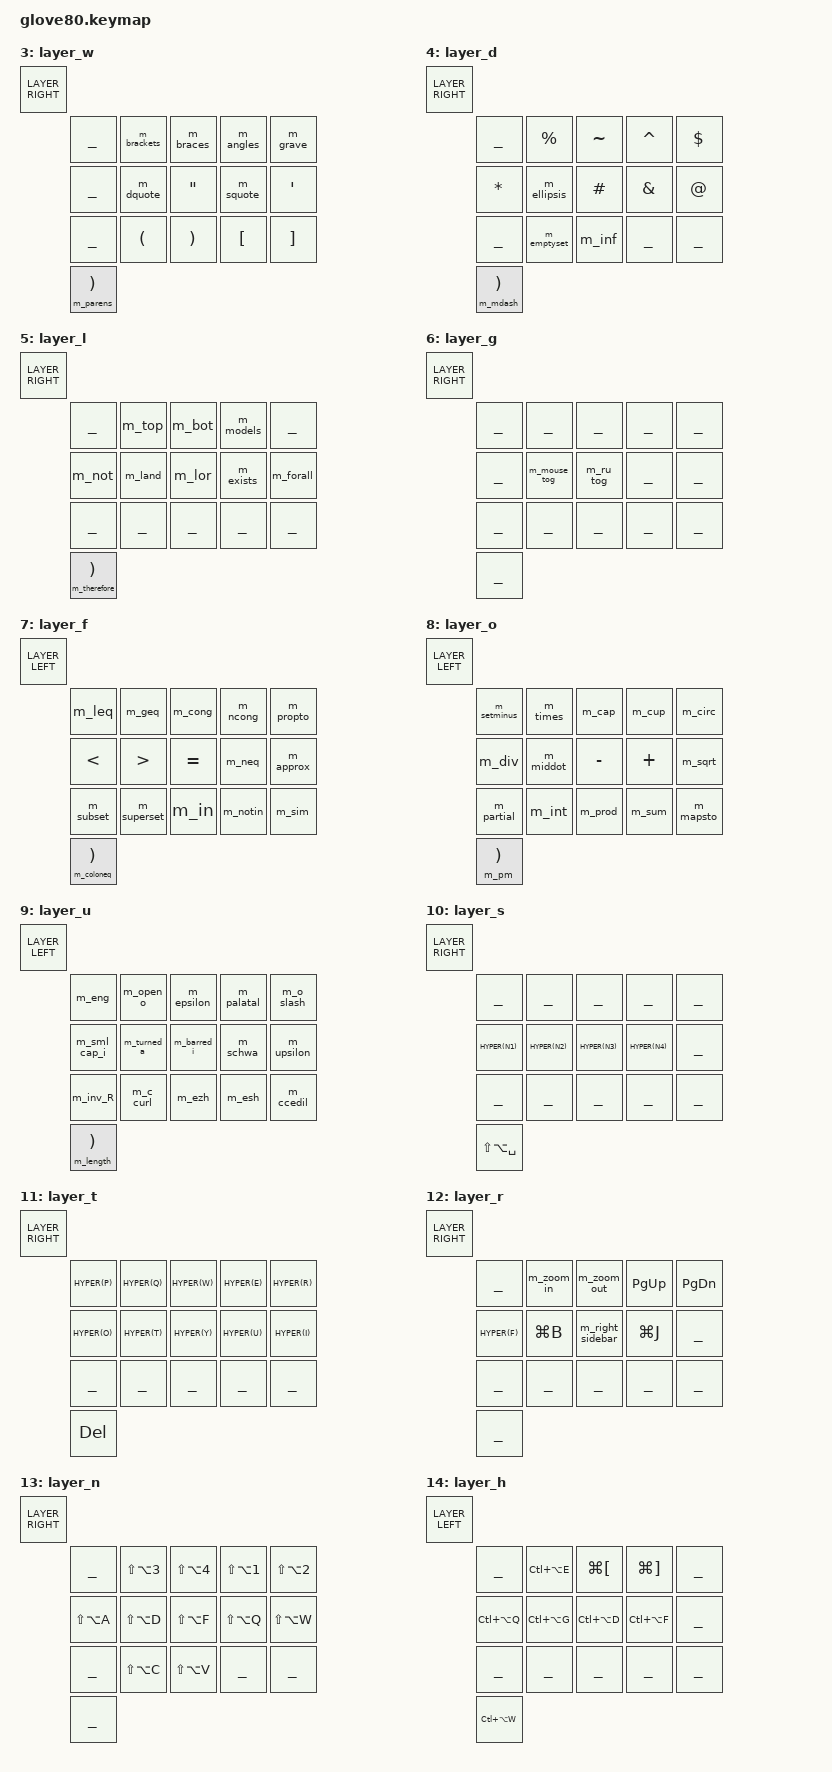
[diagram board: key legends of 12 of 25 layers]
/*
 * Glove80 keymap — QWERTY alphas (HID letter codes).
 *
 * macOS input source: U.S. QWERTY. Layer holds stay on the same finger positions
 * as the old Graphite layout (e.g. Primary apps = left-index F).
 * Mac builtin layers are Goku/Karabiner (:is_built_in_keyboard only).
 *
 * Shared actions (apps, window mgmt) emit chords; Hammerspoon runs the scripts.
 * Karabiner must not handle Glove80.
 *
 * Unicode macros: F15 + 4 hex digits → Hammerspoon keyStrokes (see unicode_leader.lua).
 * No macOS Unicode Hex Input required.
 */

#include <behaviors.dtsi>
#include <dt-bindings/zmk/keys.h>
#include <dt-bindings/zmk/modifiers.h>
#include <dt-bindings/zmk/bt.h>
#include <dt-bindings/zmk/ext_power.h>
#include <dt-bindings/zmk/outputs.h>
#include <dt-bindings/zmk/rgb.h>
#include <dt-bindings/zmk/pointing.h>

#include "layout_helpers.dtsi"

// Layer indices — must match declaration order in `keymap` below.
// L_RU must sit *below* letter/thumb layers so hold-layers still win while Russian is on.
#define DEFAULT 0
#define L_RU    1   // Vestnik Russian (tap RCTRL) — under letter layers
#define LOWER   2
#define L_W     3   // QWERTY R — Dual punctuation (was Graphite W)
#define L_D     4   // QWERTY E — Solo punctuation (was Graphite D)
#define L_L     5   // QWERTY W — Logic symbols (was Graphite L)
#define L_G     6   // hold G — J toggles mouse, K toggles Russian
#define L_F     7   // QWERTY U — Math relations (was Graphite F)
#define L_O     8   // QWERTY I — Math operators (was Graphite O)
#define L_U     9   // QWERTY O — IPA (was Graphite U)
#define L_S     10  // QWERTY F — Primary apps (was Graphite S)
#define L_T     11  // QWERTY D — Secondary apps (was Graphite T)
#define L_R     12  // QWERTY S — Inner app nav (was Graphite R)
#define L_N     13  // QWERTY A — Window management (was Graphite N)
#define L_H     14  // QWERTY J — Browser (was Graphite H)
#define L_A     15  // QWERTY K — Clipboard (was Graphite A)
#define L_E     16  // QWERTY L — Text selection (was Graphite E)
#define L_I     17  // QWERTY ; — Find & navigate (was Graphite I)
#define L_AUDIO 18  // LT5 hold — Audio & display
#define L_WNAV  19  // QWERTY , hold — Word navigation (was Graphite .)
#define L_WDEL  20  // QWERTY M hold — Word deletion (was Graphite P)
#define L_GAME  21  // tap RT3 — plain keys (no letter/thumb layers)
#define L_MOUSE 22  // hold G, tap J — mouse (bottom-row move)
#define MAGIC   23
#define FACTORY_TEST 24

// Built-in layer-tap (&lt): hold → momentary layer, tap → key.
&lt {
    flavor = "tap-preferred";
    tapping-term-ms = <280>;
    quick-tap-ms = <280>;
};

/ {
    behaviors {
        // Stock Lower: hold = momentary, double-tap = toggle
        layer_td: tap_dance_0 {
            compatible = "zmk,behavior-tap-dance";
            label = "LAYER_TAP_DANCE";
            #binding-cells = <0>;
            tapping-term-ms = <200>;
            bindings = <&mo LOWER>, <&to LOWER>;
        };

        magic: magic_hold_tap {
            compatible = "zmk,behavior-hold-tap";
            label = "MAGIC_HOLD_TAP";
            #binding-cells = <2>;
            flavor = "tap-preferred";
            tapping-term-ms = <200>;
            bindings = <&mo>, <&rgb_ug_status_macro>;
        };

        // QWERTY comma: tap , / shift < ; hold → Word-Nav
        mm_comma: mod_morph_comma {
            compatible = "zmk,behavior-mod-morph";
            #binding-cells = <0>;
            bindings = <&kp COMMA>, <&kp LT>;
            mods = <(MOD_LSFT|MOD_RSFT)>;
        };
        comma_wnav: hold_tap_comma_wnav {
            compatible = "zmk,behavior-hold-tap";
            #binding-cells = <2>;
            flavor = "tap-preferred";
            tapping-term-ms = <280>;
            bindings = <&mo>, <&mm_comma>;
        };
        // Bracket keys: [/{ and ]/} (stock QWERTY)
        mm_lbkt: mod_morph_lbkt {
            compatible = "zmk,behavior-mod-morph";
            #binding-cells = <0>;
            bindings = <&kp LBKT>, <&kp LBRC>;
            mods = <(MOD_LSFT|MOD_RSFT)>;
        };
        mm_rbkt: mod_morph_rbkt {
            compatible = "zmk,behavior-mod-morph";
            #binding-cells = <0>;
            bindings = <&kp RBKT>, <&kp RBRC>;
            mods = <(MOD_LSFT|MOD_RSFT)>;
        };
    };

    macros {
        rgb_ug_status_macro: rgb_ug_status_macro_0 {
            label = "RGB_UG_STATUS";
            compatible = "zmk,behavior-macro";
            #binding-cells = <0>;
            bindings = <&rgb_ug RGB_STATUS>;
        };

        bt_0: bt_profile_macro_0 {
            label = "BT_0";
            compatible = "zmk,behavior-macro";
            #binding-cells = <0>;
            bindings = <&out OUT_BLE>, <&bt BT_SEL 0>;
        };
        bt_1: bt_profile_macro_1 {
            label = "BT_1";
            compatible = "zmk,behavior-macro";
            #binding-cells = <0>;
            bindings = <&out OUT_BLE>, <&bt BT_SEL 1>;
        };
        bt_2: bt_profile_macro_2 {
            label = "BT_2";
            compatible = "zmk,behavior-macro";
            #binding-cells = <0>;
            bindings = <&out OUT_BLE>, <&bt BT_SEL 2>;
        };
        bt_3: bt_profile_macro_3 {
            label = "BT_3";
            compatible = "zmk,behavior-macro";
            #binding-cells = <0>;
            bindings = <&out OUT_BLE>, <&bt BT_SEL 3>;
        };

        // Shift+/ morph target: bare BSLH while Shift is still held → pipe on macOS.
        m_bslash: m_bslash {
            compatible = "zmk,behavior-macro";
            #binding-cells = <0>;
            wait-ms = <0>;
            tap-ms = <5>;
            bindings
                = <&macro_release &kp LSHFT>
                , <&macro_release &kp RSHFT>
                , <&macro_tap &kp BSLH>;
        };

        // Explicit mod order for app zoom (F3/F4 + R-layer F/O)
        m_zoom_in: m_zoom_in {
            compatible = "zmk,behavior-macro";
            #binding-cells = <0>;
            wait-ms = <0>;
            tap-ms = <5>;
            bindings
                = <&macro_press &kp LGUI>
                , <&macro_tap &kp EQUAL>
                , <&macro_release &kp LGUI>;
        };
        m_zoom_out: m_zoom_out {
            compatible = "zmk,behavior-macro";
            #binding-cells = <0>;
            wait-ms = <0>;
            tap-ms = <5>;
            bindings
                = <&macro_press &kp LGUI>
                , <&macro_tap &kp MINUS>
                , <&macro_release &kp LGUI>;
        };

        // Cmd+Opt+B — reliable mod order for Cursor auxiliary / chat sidebar
        m_right_sidebar: m_right_sidebar {
            compatible = "zmk,behavior-macro";
            #binding-cells = <0>;
            wait-ms = <0>;
            tap-ms = <5>;
            bindings
                = <&macro_press &kp LGUI>
                , <&macro_press &kp LALT>
                , <&macro_tap &kp B>
                , <&macro_release &kp LALT>
                , <&macro_release &kp LGUI>;
        };

        // Dual punctuation wrappers (type pair, cursor between)
        WRAP(m_parens,   LPAR,  RPAR);
        WRAP(m_brackets, LBKT,  RBKT);
        WRAP(m_braces,   LBRC,  RBRC);
        WRAP(m_dquote,   DQT,   DQT);
        WRAP(m_squote,   SQT,   SQT);
        WRAP(m_grave,    GRAVE, GRAVE);
        UC2_LEFT(m_angles, N2, N7, E, N8, N2, N7, E, N9); // ⟨⟩ then Left

        // macOS Unicode Hex Input (Option + 4 hex digits)
        UC(m_equiv,     N2, N2, N6, N1); // ≡
        UC(m_nequiv,    N2, N2, N6, N2); // ≢
        UC(m_sim,       N2, N2, N3, C);  // ∼
        UC(m_approx,    N2, N2, N4, N8); // ≈
        UC(m_coloneq,   N2, N2, N5, N4); // ≔
        UC(m_in,        N2, N2, N0, N8); // ∈
        UC(m_notin,     N2, N2, N0, N9); // ∉
        UC(m_subseteq,  N2, N2, N8, N6); // ⊆
        UC(m_supseteq,  N2, N2, N8, N7); // ⊇
        UC(m_subset,    N2, N2, N8, N2); // ⊂
        UC(m_superset,  N2, N2, N8, N3); // ⊃
        UC(m_nsubset,   N2, N2, N8, N4); // ⊄
        UC(m_nsuperset, N2, N2, N8, N5); // ⊅
        UC(m_cong,      N2, N2, N4, N5); // ≅
        UC(m_ncong,     N2, N2, N4, N7); // ≇
        UC(m_propto,    N2, N2, N1, D);  // ∝
        UC(m_ni,        N2, N2, N0, B);  // ∋
        UC(m_notni,     N2, N2, N0, C);  // ∌
        UC(m_circ,      N2, N2, N1, N8); // ∘
        UC(m_mapsto,    N2, N1, A,  N6); // ↦
        UC(m_times,     N0, N0, D,  N7); // ×
        UC(m_div,       N0, N0, F,  N7); // ÷
        UC(m_sqrt,      N2, N2, N1, A);  // √
        UC(m_cap,       N2, N2, N2, N9); // ∩
        UC(m_cup,       N2, N2, N2, A);  // ∪
        UC(m_setminus,  N2, N2, N1, N6); // ∖
        UC(m_sum,       N2, N2, N1, N1); // ∑
        UC(m_prod,      N2, N2, N0, F);  // ∏
        UC(m_int,       N2, N2, N2, B);  // ∫
        UC(m_partial,   N2, N2, N0, N2); // ∂
        UC(m_lrarr,     N2, N1, N9, N4); // ↔
        UC(m_oplus,     N2, N2, N9, N5); // ⊕
        UC(m_otimes,    N2, N2, N9, N7); // ⊗
        UC(m_odot,      N2, N2, N9, N9); // ⊙
        UC(m_rarr,      N2, N1, N9, N2); // →
        UC(m_larr,      N2, N1, N9, N0); // ←
        UC(m_uarr,      N2, N1, N9, N1); // ↑
        UC(m_darr,      N2, N1, N9, N3); // ↓
        UC(m_land,      N2, N2, N2, N7); // ∧
        UC(m_lor,       N2, N2, N2, N8); // ∨
        UC(m_exists,    N2, N2, N0, N3); // ∃
        UC(m_forall,    N2, N2, N0, N0); // ∀
        UC(m_implies,   N2, N7, F,  N9); // ⟹
        UC(m_iff,       N2, N7, F,  A);  // ⟺
        UC(m_vdash,     N2, N2, A,  N2); // ⊢
        UC(m_models,    N2, N2, A,  N8); // ⊨
        UC(m_top,       N2, N2, A,  N4); // ⊤
        UC(m_bot,       N2, N2, A,  N5); // ⊥
        UC(m_therefore, N2, N2, N3, N4); // ∴
        UC(m_inf,       N2, N2, N1, E);  // ∞
        UC(m_emptyset,  N2, N2, N0, N5); // ∅
        UC(m_ellipsis,  N2, N0, N2, N6); // …
        UC(m_mdash,     N2, N0, N1, N4); // —
        UC(m_leq,       N2, N2, N6, N4); // ≤
        UC(m_geq,       N2, N2, N6, N5); // ≥
        UC(m_neq,       N2, N2, N6, N0); // ≠
        UC(m_middot,    N0, N0, B,  N7); // ·
        UC(m_pm,        N0, N0, B,  N1); // ±

        // IPA (Graphite U) — RU > DE > EN, non-Latin, by frequency
        UC(m_palatal,   N0, N2, B,  N2); // ʲ
        UC(m_schwa,     N0, N2, N5, N9); // ə
        UC(m_barred_i,  N0, N2, N6, N8); // ɨ
        UC(m_esh,       N0, N2, N8, N3); // ʃ
        UC(m_ezh,       N0, N2, N9, N2); // ʒ
        UC(m_c_curl,    N0, N2, N5, N5); // ɕ
        UC(m_turned_a,  N0, N2, N5, N0); // ɐ
        UC(m_ccedil,    N0, N0, E,  N7); // ç
        UC(m_inv_R,     N0, N2, N8, N1); // ʁ
        UC(m_eng,       N0, N1, N4, B);  // ŋ
        UC(m_sml_cap_i, N0, N2, N6, A);  // ɪ
        UC(m_upsilon,   N0, N2, N8, A);  // ʊ
        UC(m_open_o,    N0, N2, N5, N4); // ɔ
        UC(m_epsilon,   N0, N2, N5, B);  // ɛ
        UC(m_o_slash,   N0, N0, F,  N8); // ø
        UC(m_length,    N0, N2, D,  N0); // ː

        UC(m_not,       N0, N0, A,  C);  // ¬

#include "russian_macros.inc"
    };

    behaviors {
#include "russian_behaviors.inc"
    };

    keymap {
        compatible = "zmk,keymap";

        // =====================================================================
        // DEFAULT — QWERTY letter HID
        //   q w e r t  y u i o p
        //   a s d f g  h j k l ;
        //   z x c v b  n m , . /
        // =====================================================================
        default_layer {
            // ---------------------------------------------------------------------------------------------------------------------------------
            // | BRIDN | BRIUP | ZOOM+ | ZOOM- | none |                                                               | NEXT  |  PP   | MUTE | VOLDN | VOLUP |
            // | none  |  1  |  2  |  3   |  4   |  5   |                                                 |  6   |   7   |   8   |  9   |   0   |  =/+ |
            // |  ESC  |  B  |  L  |  D   |  W   |  Z   |                                                 |  ,   |   F   |   O   |  U   |   J   |   \  |
            // | none  |  N  |  R  |  T   |  S   |  G   |                                                 |  Y   |   H   |   A   |  E   |   I   |   '  |
            // | none  |  Q  |  X  |  M   |  C   |  V   | LSHFT | LCTRL | LGUI  | | RGUI  | RU/RC | RSHFT |  K   |   P   |   .   |  -   |   /   | none |
            // | MAGIC | none | none | LEFT | RIGHT|      | BSPC  | TAB   | CAPS  | | RALT  | RET   | SPACE |      |  UP   | DOWN  |  [   |   ]   | none |
            // Thumbs (see keybindings.txt THUMB KEY IDS):
            // LT1/RT1 tap Caps, hold Shift; LT2 Ctrl; LT3 Cmd
            // LT4 Bspc; LT5 Audio hold (tap none); LT6 Tab
            // RT2 Ctrl(+RU tap); RT3 Cmd(+game tap); RT4–6 Space|Enter|Alt
            // Word-Nav = hold Graphite . ; Word-Del = hold Graphite P
            // Under Esc = left click; right of ; / ] = PgUp / PgDn

            bindings = <
            &kp C_BRI_DN   &kp C_BRI_UP &m_zoom_in   &m_zoom_out  &none                                                                                         &kp C_NEXT &kp C_PP    &kp C_MUTE  &kp C_VOL_DN &kp C_VOL_UP
            &none          &kp N1   &kp N2      &kp N3      &kp N4      &kp N5                                                                     &kp N6  &kp N7  &kp N8      &kp N9      &kp N0      &kp EQUAL
            &kp ESC        &kp Q     &lt L_L W   &lt L_D E   &lt L_W R   &kp T                                                                      &kp Y   &lt L_F U  &lt L_O I  &lt L_U O  &kp P       &kp BSLH
            &mkp LCLK      &lt L_N A &lt L_R S  &lt L_T D   &lt L_S F   &lt L_G G                                                                  &kp H   &lt L_H J  &lt L_A K  &lt L_E L  &lt L_I SEMI   &kp SQT
            &none          &kp Z    &kp X       &kp C       &kp V       &kp B   &shift_caps LSHFT CAPS   &kp LCTRL   &kp LGUI  &game_cmd RGUI 0  &ru_on RCTRL 0 &shift_caps RSHFT CAPS   &kp N   &lt L_WDEL M   &comma_wnav L_WNAV 0   &kp DOT   &kp FSLH    &kp PG_UP
            &magic MAGIC 0 &none &none &kp LEFT &kp RIGHT        &kp BSPC    &mo L_AUDIO &kp TAB &kp RALT &kp RET &kp SPACE &kp UP &kp DOWN &mm_lbkt &mm_rbkt &kp PG_DN
            >;
        };

        // =====================================================================
        // RUSSIAN — Vestnik (same QWERTY letters; HS remaps to Cyrillic)
        // Same edges/thumbs as default except LT5 tap = stress.
        // =====================================================================
        russian_layer {
            bindings = <
            &kp C_BRI_DN   &kp C_BRI_UP &m_zoom_in   &m_zoom_out  &none                                                                                         &kp C_NEXT &kp C_PP    &kp C_MUTE  &kp C_VOL_DN &kp C_VOL_UP
            &none          &kp N1   &kp N2      &kp N3      &kp N4      &kp N5                                                                     &kp N6  &kp N7  &kp N8      &kp N9      &kp N0      &kp EQUAL
            &kp ESC        &kp Q        &lt L_L W   &lt L_D E   &lt L_W R   &kp T                                                                        &kp Y &lt L_F U &lt L_O I &lt L_U O &kp P &kp BSLH
            &mkp LCLK      &lt L_N A    &lt L_R S   &lt L_T D   &lt L_S F   &lt L_G G                                                                    &kp H &lt L_H J &lt L_A K &lt L_E L &lt L_I SEMI &kp SQT
            &none          &kp Z        &kp X       &kp C       &kp V       &kp B   &shift_caps LSHFT CAPS &kp LCTRL &kp LGUI  &game_cmd RGUI 0  &ru_off RCTRL 0 &shift_caps RSHFT CAPS   &kp N &lt L_WDEL M &lt L_WNAV COMMA &kp DOT &kp FSLH &kp PG_UP
            &magic MAGIC 0 &none        &none       &kp LEFT    &kp RIGHT                    &kp BSPC &ru_tab L_AUDIO 0 &kp TAB &kp RALT &kp RET &kp SPACE &kp UP &kp DOWN &kp LBKT &kp RBKT &kp PG_DN
            >;
        };

        // Stock Lower layer (unchanged from MoErgo default)
        lower_layer {
            bindings = <
            &kp C_BRI_DN      &kp C_BRI_UP        &kp C_PREV      &kp C_NEXT      &kp C_PP                                                                                                           &kp C_MUTE   &kp C_VOL_DN &kp C_VOL_UP  &none           &kp PAUSE_BREAK
            &trans            &none               &none           &none           &none           &kp HOME                                                                              &kp LPAR     &kp KP_NUM   &kp KP_EQUAL &kp KP_DIVIDE &kp KP_MULTIPLY &kp PSCRN
            &trans            &none               &none           &kp UP          &none           &kp END                                                                               &kp RPAR     &kp KP_N7    &kp KP_N8    &kp KP_N9     &kp KP_MINUS    &kp SLCK
            &trans            &none               &kp LEFT        &kp DOWN        &kp RIGHT       &kp PG_UP                                                                             &kp PRCNT    &kp KP_N4    &kp KP_N5    &kp KP_N6     &kp KP_PLUS     &none
            &trans            &kp K_CMENU         &none           &kp F11         &kp F12         &kp PG_DN       &trans      &trans      &to DEFAULT &trans      &trans      &trans    &kp COMMA    &kp KP_N1    &kp KP_N2    &kp KP_N3     &kp KP_ENTER    &trans
            &trans            &kp CAPS            &kp INS         &kp F11         &kp F12                         &trans      &trans      &trans      &trans      &trans      &trans                 &kp KP_N0    &kp KP_N0    &kp KP_DOT    &kp KP_ENTER    &trans
            >;
        };

        // =====================================================================
        // Layers — opposite-hand only via LAYER_LEFT / LAYER_RIGHT
        // Args are QWERTY positions; comments note Graphite roles.
        // LAYER_RIGHT(y,u,i,o,p,  h,j,k,l,;,  n,m,,,.,/,  space)
        // LAYER_LEFT (q,w,e,r,t,  a,s,d,f,g,  z,x,c,v,b,  space)
        // =====================================================================

        // =====================================================================
        // UPPER LEFT (inward → outward): W D L
        // =====================================================================

        // Graphite W, QWERTY R — Dual punctuation
        // Upper: wrap pairs; home: quotes; bottom: single open/close; Space = ()
        layer_w {
            bindings = <
            LAYER_RIGHT(
                ___, &m_brackets, &m_braces, &m_angles, &m_grave,
                ___, &m_dquote, &kp DQT, &m_squote, &kp SQT,
                ___, &kp LPAR, &kp RPAR, &kp LBKT, &kp RBKT,
                &m_parens
            )
            >;
        };

        // Graphite D, QWERTY E — Solo punctuation
        layer_d {
            bindings = <
            LAYER_RIGHT(
                ___, &kp PRCNT, &kp TILDE, &kp CARET, &kp DLLR,
                &kp STAR, &m_ellipsis, &kp HASH, &kp AMPS, &kp AT,
                ___, &m_emptyset, &m_inf, ___, ___,
                &m_mdash
            )
            >;
        };

        // Graphite L, QWERTY W — Logic symbols (was B)
        // F⊤ O⊥ U⊨ | Y¬ H∧ A∨ E∃ I∀ | Space∴
        layer_l {
            bindings = <
            LAYER_RIGHT(
                ___, &m_top, &m_bot, &m_models, ___,
                &m_not, &m_land, &m_lor, &m_exists, &m_forall,
                ___, ___, ___, ___, ___,
                &m_therefore
            )
            >;
        };

        // Hold G: H = toggle mouse, A = toggle Russian
        layer_g {
            bindings = <
            LAYER_RIGHT(
                ___, ___, ___, ___, ___,
                ___, &m_mouse_tog, &m_ru_tog, ___, ___,
                ___, ___, ___, ___, ___,
                ___
            )
            >;
        };

        // =====================================================================
        // UPPER RIGHT (inward → outward): F O U
        // =====================================================================

        // Graphite F, QWERTY U — Math relations (rows cycled LEFT)
        // B≤ L≥ D≅ W≇ Z∝ | N< R> T= S≠ G≈ | Q⊂ X⊃ M∈ C∉ V∼ | Space≔
        layer_f {
            bindings = <
            LAYER_LEFT(
                &m_leq, &m_geq, &m_cong, &m_ncong, &m_propto,
                &kp LT, &kp GT, &kp EQUAL, &m_neq, &m_approx,
                &m_subset, &m_superset, &m_in, &m_notin, &m_sim,
                &m_coloneq
            )
            >;
        };

        // Graphite O, QWERTY I — Math operators
        // B∖ L× D∩ W∪ Z∘ | N÷ R· T- S+ G√ | Q∂ X∫ M∏ C∑ V↦ | Space±
        layer_o {
            bindings = <
            LAYER_LEFT(
                &m_setminus, &m_times, &m_cap, &m_cup, &m_circ,
                &m_div, &m_middot, &kp MINUS, &kp PLUS, &m_sqrt,
                &m_partial, &m_int, &m_prod, &m_sum, &m_mapsto,
                &m_pm
            )
            >;
        };

        // Graphite U, QWERTY O — IPA (upper↔middle flipped)
        // Bŋ Lɔ Dɛ Wʲ Zø | Nɪ Rɐ Tɨ Sə Gʊ | Qʁ Xɕ Mʒ Cʃ Vç | Spaceː
        layer_u {
            bindings = <
            LAYER_LEFT(
                &m_eng, &m_open_o, &m_epsilon, &m_palatal, &m_o_slash,
                &m_sml_cap_i, &m_turned_a, &m_barred_i, &m_schwa, &m_upsilon,
                &m_inv_R, &m_c_curl, &m_ezh, &m_esh, &m_ccedil,
                &m_length
            )
            >;
        };

        // =====================================================================
        // HOME LEFT (inward → outward): S T R N
        // =====================================================================

        // Graphite S, QWERTY F — Primary apps (was H; flipped to right hand)
        // Y/H/A/E = apps 1-4
        layer_s {
            bindings = <
            LAYER_RIGHT(
                ___, ___, ___, ___, ___,
                &kp HYPER(N1), &kp HYPER(N2), &kp HYPER(N3), &kp HYPER(N4), ___,
                ___, ___, ___, ___, ___,
                &kp LS(LA(SPACE))
            )
            >;
        };

        // Graphite T, QWERTY D — Secondary apps (was S)
        // Upper: F WhatsApp … J Calendar; Y Messages; , Spotify; Space = Delete
        layer_t {
            bindings = <
            LAYER_RIGHT(
                &kp HYPER(P), &kp HYPER(Q), &kp HYPER(W), &kp HYPER(E), &kp HYPER(R),
                &kp HYPER(O), &kp HYPER(T), &kp HYPER(Y), &kp HYPER(U), &kp HYPER(I),
                ___, ___, ___, ___, ___,
                &kp DEL
            )
            >;
        };

        // Graphite R, QWERTY S — Inner app nav (was A; flipped to right)
        // Y focus editor; H/A/E sidebars (Cursor: open/focus, close if focused)
        layer_r {
            bindings = <
            LAYER_RIGHT(
                ___, &m_zoom_in, &m_zoom_out, &kp PG_UP, &kp PG_DN,
                &kp HYPER(F), &kp LG(B), &m_right_sidebar, &kp LG(J), ___,
                ___, ___, ___, ___, ___,
                ___
            )
            >;
        };

        // Graphite N, QWERTY A — Window management
        // F/O send ws; U/J go ws; P/. resize; Y swap; H/A focus; E accordion; I split
        layer_n {
            bindings = <
            LAYER_RIGHT(
                ___, &kp LS(LA(N3)), &kp LS(LA(N4)), &kp LS(LA(N1)), &kp LS(LA(N2)),
                &kp LS(LA(A)), &kp LS(LA(D)), &kp LS(LA(F)), &kp LS(LA(Q)), &kp LS(LA(W)),
                ___, &kp LS(LA(C)), &kp LS(LA(V)), ___, ___,
                ___
            )
            >;
        };

        // =====================================================================
        // HOME RIGHT (inward → outward): H A E I
        // =====================================================================

        // Graphite H, QWERTY J — Browser (was T; flipped to left)
        // D/W links; L split; R new; T prev; S next; N switch spaces
        layer_h {
            bindings = <
            LAYER_LEFT(
                ___, &kp LC(LA(E)), &kp LG(LBKT), &kp LG(RBKT), ___,
                &kp LC(LA(Q)), &kp LC(LA(G)), &kp LC(LA(D)), &kp LC(LA(F)), ___,
                ___, ___, ___, ___, ___,
                &kp LC(LA(W))
            )
            >;
        };

        // Graphite A, QWERTY K — Clipboard & edit (was E)
        layer_a {
            bindings = <
            LAYER_LEFT(
                ___, ___, &kp LG(LS(V)), &kp LG(LS(Z)), ___,
                &kp LG(C), &kp LG(X), &kp LG(V), &kp LG(Z), ___,
                ___, ___, ___, ___, ___,
                &kp LG(FSLH)
            )
            >;
        };

        // Graphite E, QWERTY L — Text selection (was R; flipped to left)
        // Home: N/R word, T/S line start/end
        layer_e {
            bindings = <
            LAYER_LEFT(
                &kp LS(UP), &kp LS(DOWN), &kp LS(RIGHT), &kp LS(LEFT), ___,
                &kp LS(LA(LEFT)), &kp LS(LA(RIGHT)), &kp LS(LG(LEFT)), &kp LS(LG(RIGHT)), ___,
                ___, ___, ___, ___, ___,
                &kp LG(A)
            )
            >;
        };

        // Graphite I, QWERTY ; — Find & navigate
        // W find, D replace, L go-to-def; N rename, R/T find prev/next, S save; Space Esc
        layer_i {
            bindings = <
            LAYER_LEFT(
                ___, &kp F12, &kp LG(LA(F)), &kp LG(F), ___,
                &kp F2, &kp LG(LS(G)), &kp LG(G), &kp LG(S), ___,
                ___, ___, ___, ___, ___,
                &kp ESC
            )
            >;
        };

        // =====================================================================
        // THUMB LEFT
        // =====================================================================

        // Tab hold — Audio & display (left thumb → taps on right hand)
        layer_audio {
            bindings = <
            LAYER_RIGHT(
                ___, &kp C_BRI_UP, &kp C_BRI_DN, &kp LG(L), ___,
                ___, &m_zoom_in, &m_zoom_out, &kp C_VOL_UP, &kp C_VOL_DN,
                ___, ___, ___, ___, ___,
                ___
            )
            >;
        };

        // =====================================================================
        // THUMB RIGHT (inward → outward): Word Nav, Word Del
        // =====================================================================

        // Graphite . hold — Word navigation
        // B down, L up, D left, W right; T line start, S line end
        layer_wnav {
            bindings = <
            LAYER_LEFT(
                &kp DOWN, &kp UP, &kp LEFT, &kp RIGHT, ___,
                &kp LA(LEFT), &kp LA(RIGHT), &kp LG(LEFT), &kp LG(RIGHT), ___,
                ___, ___, ___, ___, ___,
                ___
            )
            >;
        };

        // Graphite P hold — Word deletion
        // D deindent, W indent; N/R word; T/S line; opp. thumb = Delete
        layer_wdel {
            bindings = <
            LAYER_LEFT(
                ___, ___, &kp LG(LBKT), &kp LG(RBKT), ___,
                &kp LA(BSPC), &kp LA(DEL), &kp LG(BSPC), &kp LG(DEL), ___,
                ___, ___, ___, ___, ___,
                &kp DEL
            )
            >;
        };

        // =====================================================================
        // GAME — plain Graphite (no letter/thumb hold layers). Tap RT3 to toggle.
        // F-row / numbers / Magic / most thumbs / arrows: &trans from default.
        // =====================================================================
        game_layer {
            bindings = <
            &trans         &trans       &trans      &trans      &trans                                                                                         &trans  &trans      &trans      &trans      &trans
            &trans         &trans       &trans      &trans      &trans      &trans                                                                      &trans  &trans  &trans      &trans      &trans      &trans
            &trans         &kp Q        &kp W       &kp E       &kp R       &kp T                                                                        &kp Y   &kp U   &kp I       &kp O       &kp P       &kp BSLH
            &mkp LCLK      &kp A        &kp S       &kp D       &kp F       &lt L_G G                                                                    &kp H   &kp J   &kp K       &kp L       &kp SEMI    &kp SQT
            &trans         &kp Z        &kp X       &kp C       &kp V       &kp B   &shift_caps LSHFT CAPS &kp LCTRL &kp LGUI  &game_cmd RGUI 0  &kp RCTRL &shift_caps RSHFT CAPS   &kp N &kp M &kp COMMA &kp DOT &kp FSLH &kp PG_UP
            &trans         &trans       &trans      &trans      &trans                    &trans &none &kp TAB &trans &trans &trans &trans &trans &trans &trans &kp PG_DN
            >;
        };

        // =====================================================================
        // MOUSE — hold G, tap J to toggle. Bottom row moves (overrides M/, layers).
        // F/J: tap = lock/unlock LCLK; hold = Primary apps / Browser.
        // Z left  X up  C down  V right | M up-left  , up-right  . down-left  / down-right
        // B LCLK  N RCLK
        // =====================================================================
        mouse_layer {
            bindings = <
            &trans         &trans       &trans      &trans      &trans                                                                                         &trans  &trans      &trans      &trans      &trans
            &trans         &trans       &trans      &trans      &trans      &trans                                                                      &trans  &trans  &trans      &trans      &trans      &trans
            &trans         &trans       &trans      &trans      &trans      &trans                                                                      &trans  &trans  &trans      &trans      &trans      &trans
            &trans         &trans       &trans      &trans      &mouse_s L_S 0 &trans                                                                      &trans  &mouse_h L_H 0 &trans    &trans      &trans      &trans
            &trans         &mmv MOVE_LEFT &mmv MOVE_UP &mmv MOVE_DOWN &mmv MOVE_RIGHT &mkp LCLK   &trans &trans &trans  &trans &trans &trans    &mkp RCLK &mmv MOVE(-600,-600) &mmv MOVE(600,-600) &mmv MOVE(-600,600) &mmv MOVE(600,600) &trans
            &trans         &trans       &trans      &msc SCRL_LEFT &msc SCRL_RIGHT                    &trans &trans &trans &trans &trans &trans &msc SCRL_UP &msc SCRL_DOWN &trans &trans &trans
            >;
        };

        // =====================================================================
        // MAGIC — Bluetooth / RGB / bootloader (stock Glove80)
        // =====================================================================
        magic_layer {
            bindings = <
&bt BT_CLR        &none               &none           &none           &none                                                                                                           &none      &none      &none      &none      &bt BT_CLR_ALL
&none             &none               &none           &none           &none           &none                                                                                &none      &none      &none      &none      &none      &none
&none             &rgb_ug RGB_SPI     &rgb_ug RGB_SAI &rgb_ug RGB_HUI &rgb_ug RGB_BRI &rgb_ug RGB_TOG                                                                      &none      &none      &none      &none      &none      &none
&bootloader       &rgb_ug RGB_SPD     &rgb_ug RGB_SAD &rgb_ug RGB_HUD &rgb_ug RGB_BRD &rgb_ug RGB_EFF                                                                      &none      &none      &none      &none      &none      &bootloader
&sys_reset        &none               &none           &none           &none           &none           &bt_2     &bt_3     &none            &none     &none     &none       &none      &none      &none      &none      &none      &sys_reset
&none             &none               &none           &none           &none                           &bt_0     &bt_1     &out OUT_USB     &none     &none     &none                  &none      &none      &none      &none      &to FACTORY_TEST
            >;
        };

        factory_test_layer {
            bindings = <
&kp N0   &kp N6   &kp N2   &kp N8   &kp N4                                                                              &kp N4   &kp N8   &kp N2   &kp N6   &kp N0
&kp N1   &kp N7   &kp N3   &kp N9   &kp N5   &kp N0                                                            &kp N0   &kp N5   &kp N9   &kp N3   &kp N7   &kp N1
&kp N2   &kp N8   &kp N4   &kp N0   &kp N6   &kp N1                                                            &kp N1   &kp N6   &kp N0   &kp N4   &kp N8   &kp N2
&kp N3   &kp N9   &kp N5   &kp N1   &kp N7   &kp N2                                                            &kp N2   &kp N7   &kp N1   &kp N5   &kp N9   &kp N3
&kp N4   &kp N0   &kp N6   &kp N2   &kp N8   &kp N3   &kp N4   &kp N5   &kp N6      &kp N6   &kp N5   &kp N4   &kp N3   &kp N8   &kp N2   &kp N6   &kp N0   &kp N4
&kp N5   &kp N1   &kp N7   &kp N3   &kp N9            &kp N7   &kp N8   &kp N9      &kp N9   &kp N8   &kp N7            &kp N9   &kp N3   &kp N7   &kp N1   &kp N5
            >;
        };
    };
};
